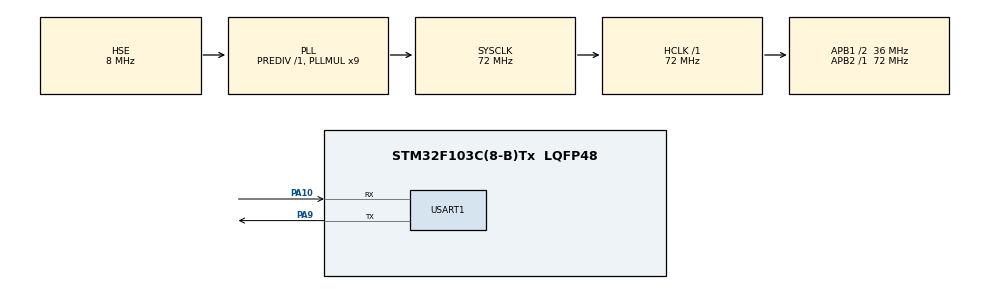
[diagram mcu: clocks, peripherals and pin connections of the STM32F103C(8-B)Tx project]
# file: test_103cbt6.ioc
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Dma.Request0=USART1_RX
Dma.Request1=USART1_TX
Dma.USART1_RX.0.Direction=DMA_PERIPH_TO_MEMORY
Dma.USART1_RX.0.Instance=DMA1_Channel5
Dma.USART1_RX.0.MemDataAlignment=DMA_MDATAALIGN_BYTE
Dma.USART1_RX.0.MemInc=DMA_MINC_ENABLE
Dma.USART1_RX.0.Mode=DMA_CIRCULAR
Dma.USART1_RX.0.PeriphDataAlignment=DMA_PDATAALIGN_BYTE
Dma.USART1_RX.0.PeriphInc=DMA_PINC_DISABLE
Dma.USART1_RX.0.Priority=DMA_PRIORITY_LOW
Dma.USART1_TX.1.Direction=DMA_MEMORY_TO_PERIPH
Dma.USART1_TX.1.Instance=DMA1_Channel4
Dma.USART1_TX.1.MemDataAlignment=DMA_MDATAALIGN_BYTE
Dma.USART1_TX.1.MemInc=DMA_MINC_ENABLE
Dma.USART1_TX.1.Mode=DMA_CIRCULAR
Dma.USART1_TX.1.PeriphDataAlignment=DMA_PDATAALIGN_BYTE
Dma.USART1_TX.1.PeriphInc=DMA_PINC_DISABLE
Dma.USART1_TX.1.Priority=DMA_PRIORITY_LOW
Mcu.Family=STM32F1
Mcu.Name=STM32F103C(8-B)Tx
Mcu.Package=LQFP48
NVIC.DMA1_Channel4_IRQn=true\:0\:0\:false\:false\:true\:false\:true\:true
NVIC.DMA1_Channel5_IRQn=true\:0\:0\:false\:false\:true\:false\:true\:true
NVIC.PriorityGroup=NVIC_PRIORITYGROUP_4
NVIC.USART1_IRQn=true\:0\:0\:false\:false\:true\:true\:true\:true
PA10.Mode=Asynchronous
PA10.Signal=USART1_RX
PA13.Mode=JTAG_5_pins
PA13.Signal=SYS_JTMS-SWDIO
PA14.Mode=JTAG_5_pins
PA14.Signal=SYS_JTCK-SWCLK
PA15.Mode=JTAG_5_pins
PA15.Signal=SYS_JTDI
PA9.Mode=Asynchronous
PA9.Signal=USART1_TX
PB3.Mode=JTAG_5_pins
PB3.Signal=SYS_JTDO-TRACESWO
PB4.Mode=JTAG_5_pins
PB4.Signal=SYS_NJTRST
PD0-OSC_IN.Mode=HSE-External-Oscillator
PD0-OSC_IN.Signal=RCC_OSC_IN
PD1-OSC_OUT.Mode=HSE-External-Oscillator
PD1-OSC_OUT.Signal=RCC_OSC_OUT
ProjectManager.HeapSize=0x200
ProjectManager.StackSize=0x400
ProjectManager.TargetToolchain=Makefile
RCC.AHBFreq_Value=72000000
RCC.APB1CLKDivider=RCC_HCLK_DIV2
RCC.APB1Freq_Value=36000000
RCC.APB1TimFreq_Value=72000000
RCC.APB2Freq_Value=72000000
RCC.APB2TimFreq_Value=72000000
RCC.HCLKFreq_Value=72000000
RCC.PLLMUL=RCC_PLL_MUL9
RCC.PLLSourceVirtual=RCC_PLLSOURCE_HSE
RCC.SYSCLKFreq_VALUE=72000000
RCC.SYSCLKSource=RCC_SYSCLKSOURCE_PLLCLK
RCC.USBFreq_Value=72000000
USART1.VirtualMode=VM_ASYNC
board=custom

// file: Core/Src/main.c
/* USER CODE BEGIN Header */
/**
  ******************************************************************************
  * @file           : main.c
  * @brief          : Main program body
  ******************************************************************************
  * @attention
  *
  * Copyright (c) 2026 STMicroelectronics.
  * All rights reserved.
  *
  * This software is licensed under terms that can be found in the LICENSE file
  * in the root directory of this software component.
  * If no LICENSE file comes with this software, it is provided AS-IS.
  *
  ******************************************************************************
  */
/* USER CODE END Header */
#include "main.h"
#include "dma.h"
#include "usart.h"
#include "gpio.h"
#include "smf.h"
#include "command.h"
#include <string.h>
#include <stdio.h>

/* USER CODE BEGIN PV */

/**
 * @brief 全局变量定义
 */

/**
 * @brief 状态机上下文
 *
 * 包含状态机的当前状态和相关计数器
 */
struct app_smf_ctx g_app_smf_ctx;

/**
 * @brief 状态指针定义
 *
 * 指向状态机的四个状态：初始化、空闲、工作和错误状态
 */
struct smf_state *g_state_init;      // 初始化状态指针
struct smf_state *g_state_idle;      // 空闲状态指针
struct smf_state *g_state_working;   // 工作状态指针
struct smf_state *g_state_error;     // 错误状态指针

/**
 * @brief 串口接收相关变量
 *
 * 从usart.c文件外部声明的变量
 */
extern volatile uint8_t uart_rx_flag;     // 接收完成标志
extern volatile uint16_t uart_rx_count;   // 接收数据计数
extern volatile uint8_t uart_user_buffer[]; // 用户数据缓冲区
extern volatile uint16_t uart_user_len;   // 用户数据长度

/* USER CODE END PV */

void SystemClock_Config(void);

/* Private user code ---------------------------------------------------------
USER CODE BEGIN 0 */

/* USER CODE END 0 */

int main(void)
{

  /* MCU Configuration--------------------------------------------------------*/

  /* Reset of all peripherals, Initializes the Flash interface and the Systick. */
  HAL_Init();

  /* Configure the system clock */
  SystemClock_Config();

  /* Initialize all configured peripherals */
  MX_GPIO_Init();     // 初始化GPIO
  MX_DMA_Init();      // 初始化DMA
  MX_USART1_UART_Init();  // 初始化USART1

  /* USER CODE BEGIN 2 */

  // 初始化 DMA 接收中断模式（支持不定长数据接收）
  UART_DMA_Receive_IT_Init();

  // 发送欢迎信息
  char welcome_msg[] = "\r\n=== STM32F103 UART Demo ===\r\n";
  char menu_msg[] = "DMA + IDLE Interrupt Mode Ready!\r\n";
  char prompt_msg[] = "Echo mode enabled. Type something...\r\n";

  // 等待串口就绪
  HAL_Delay(100);

  // 发送欢迎信息
  UART_SendData((uint8_t*)welcome_msg, strlen(welcome_msg));
  HAL_Delay(50);
  UART_SendData((uint8_t*)menu_msg, strlen(menu_msg));
  HAL_Delay(50);
  UART_SendData((uint8_t*)prompt_msg, strlen(prompt_msg));

  // 初始化状态机
  state_machine_init();

  /* USER CODE END 2 */

  /* Infinite loop */
  while (1)
  {

    /* USER CODE BEGIN 3 */
    // 检查是否有新数据接收
    if (uart_rx_flag)
    {
        // 处理接收到的数据 - 使用HAL库标准回调函数
        HAL_UART_RxCpltCallback(&huart1);

        // 清除标志位
        uart_rx_flag = 0;
    }

    // 运行状态机
    smf_run_state(&g_app_smf_ctx.ctx);

    // 短暂延时，避免占用过多CPU资源
    HAL_Delay(1);
  }
  /* USER CODE END 3 */
}

void SystemClock_Config(void)
{
  RCC_OscInitTypeDef RCC_OscInitStruct = {0};
  RCC_ClkInitTypeDef RCC_ClkInitStruct = {0};

  /** Initializes the RCC Oscillators according to the specified parameters
  * in the RCC_OscInitTypeDef structure.
  */
  RCC_OscInitStruct.OscillatorType = RCC_OSCILLATORTYPE_HSE;
  RCC_OscInitStruct.HSEState = RCC_HSE_ON;
  RCC_OscInitStruct.HSEPredivValue = RCC_HSE_PREDIV_DIV1;
  RCC_OscInitStruct.HSIState = RCC_HSI_ON;
  RCC_OscInitStruct.PLL.PLLState = RCC_PLL_ON;
  RCC_OscInitStruct.PLL.PLLSource = RCC_PLLSOURCE_HSE;
  RCC_OscInitStruct.PLL.PLLMUL = RCC_PLL_MUL9;
  if (HAL_RCC_OscConfig(&RCC_OscInitStruct) != HAL_OK)
  {
    Error_Handler();
  }

  /** Initializes the CPU, AHB and APB buses clocks
  */
  RCC_ClkInitStruct.ClockType = RCC_CLOCKTYPE_HCLK|RCC_CLOCKTYPE_SYSCLK
                              |RCC_CLOCKTYPE_PCLK1|RCC_CLOCKTYPE_PCLK2;
  RCC_ClkInitStruct.SYSCLKSource = RCC_SYSCLKSOURCE_PLLCLK;
  RCC_ClkInitStruct.AHBCLKDivider = RCC_SYSCLK_DIV1;
  RCC_ClkInitStruct.APB1CLKDivider = RCC_HCLK_DIV2;
  RCC_ClkInitStruct.APB2CLKDivider = RCC_HCLK_DIV1;

  if (HAL_RCC_ClockConfig(&RCC_ClkInitStruct, FLASH_LATENCY_2) != HAL_OK)
  {
    Error_Handler();
  }
}

void Error_Handler(void)
{
  __disable_irq();
  while (1)
  {
  }
}
